# STM32WL3R register map
File version: 0.3
CPU: CM0+ r0p0, little endian, MPU, no FPU, 4 interrupt priority bits
Registers are 32-bit, read-write, reset 0x0 unless marked. A register's access mark holds for its fields unless they carry their own. Offsets are from the block's base; [hi:lo] are bit positions.

## DYNAMIC — DYNAMIC_REG_BLOCK address block description
Base 0x49000500
0x00 PCKTLEN_CONFIG reset 0x14
  [15:0] PCKTLEN — Length of packet in bytes for Normal mode with FIXED length mode
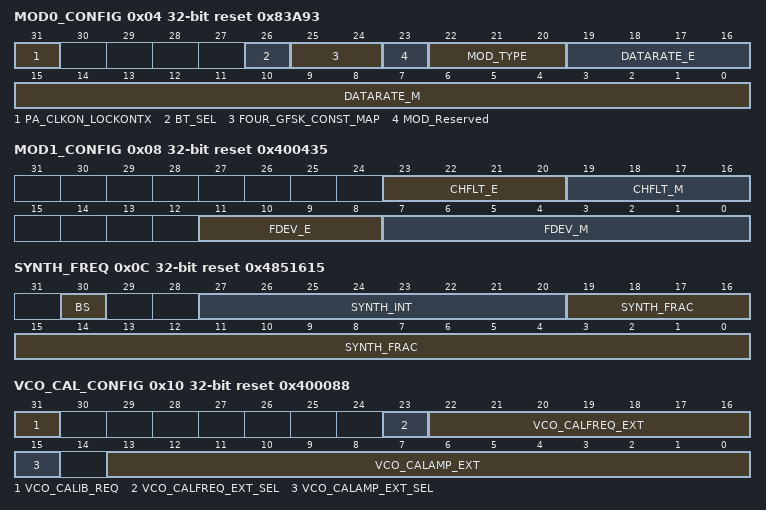
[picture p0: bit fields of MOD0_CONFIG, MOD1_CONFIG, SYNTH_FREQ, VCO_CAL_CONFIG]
0x04 MOD0_CONFIG reset 0x83A93
  [31] PA_CLKON_LOCKONTX — Enable the clock on analog PA in LOCKONTX state:
  [26] BT_SEL — Select BT value for GFSK (0.5 or 1)
  [25:24] FOUR_GFSK_CONST_MAP — 2- and 4-GFSK constellation mapping
  [23] MOD_Reserved — Free bit to expand MOD_TYPE in case more modulations to come in future evolutions
  [22:20] MOD_TYPE — Modulation type:
  [19:16] DATARATE_E — The exponent of the specified data rate (default: 38.4 ksps)
  [15:0] DATARATE_M — The Mantissa of the specified data rate (default: 38.4 ksps)
0x08 MOD1_CONFIG reset 0x400435
  [23:20] CHFLT_E — Exponent of the channel filter BW (default: 100 kHz)
  [19:16] CHFLT_M — Mantissa of the channel filter BW (default: 100 kHz)
  [11:8] FDEV_E — Exponent of the frequency deviation (default: 20 kHz)
  [7:0] FDEV_M — Mantissa of the frequency deviation (default: 20 kHz)
0x0C SYNTH_FREQ reset 0x4851615
  [30] BS — Synthesizer band selector, i.e. out-of-loop total divide factor, 4 or 8 (default: 826 MHz - 958 MHz band)
  [27:20] SYNTH_INT — PLL integer divide factor (default: 868 MHz, XTAL: 48 MHz)
  [19:0] SYNTH_FRAC — Fractional part of the PLL fractional divide factor
0x10 VCO_CAL_CONFIG reset 0x400088
  [31] VCO_CALIB_REQ — Define if the Radio FSM must launch a VCO calibration request after VCO start-up
  [23] VCO_CALFREQ_EXT_SEL — Bit to provide external VCO calfreq value through VCO_CALFREQ_EXT:
  [22:16] VCO_CALFREQ_EXT — VCO Cbank frequency calibration word.
  [15] VCO_CALAMP_EXT_SEL — Bit to provide external VCO calamp value through VCO_CALAMP_EXT:
  [13:0] VCO_CALAMP_EXT — VCO magnitude calibration word in thermometric code
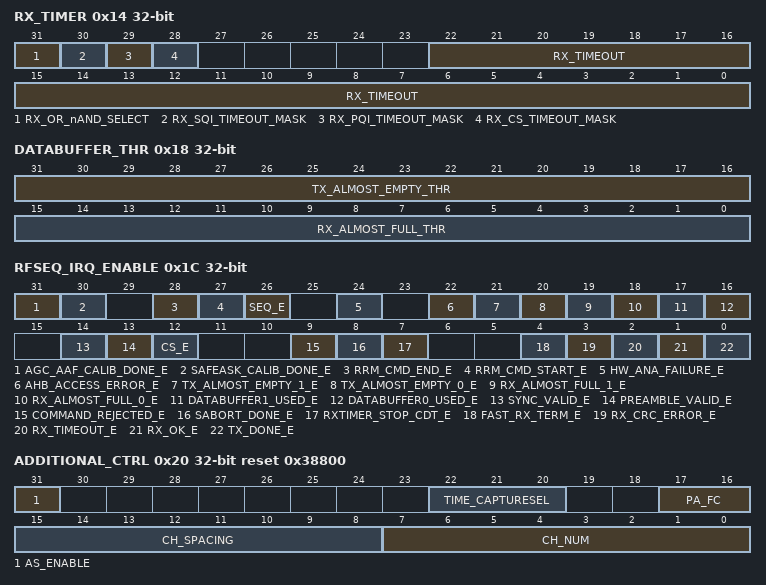
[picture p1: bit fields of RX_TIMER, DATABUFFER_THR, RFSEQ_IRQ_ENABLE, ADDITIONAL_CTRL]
0x14 RX_TIMER
  [31] RX_OR_nAND_SELECT — Select logical OR or logcial AND to apply on CS/PQI/SQI timeout mask:
  [30] RX_SQI_TIMEOUT_MASK — 1 => SQI value contributes to timeout disabling
  [29] RX_PQI_TIMEOUT_MASK — 1 => PQI value contributes to timeout disabling
  [28] RX_CS_TIMEOUT_MASK — 1 => CS value contributes to timeout disabling
  [22:0] RX_TIMEOUT — RX timer timeout (relative duration in interpolated time=machine time unit)
0x18 DATABUFFER_THR
  [31:16] TX_ALMOST_EMPTY_THR — Almost Empty threshold for TX DataBuffers.
  [15:0] RX_ALMOST_FULL_THR — Almost Full threshold for RX DataBuffers
0x1C RFSEQ_IRQ_ENABLE
  [31] AGC_AAF_CALIB_DONE_E — Enable interrupt on AGC_AAF_CALIB_DONE_F flag
  [30] SAFEASK_CALIB_DONE_E — Enable interrupt on SAFEASK_CALIB_DONE_F flag
  [28] RRM_CMD_END_E — Enable interrupt on RRM_CMD_END_F flag
  [27] RRM_CMD_START_E — Enable interrupt on RRM_CMD_START_F flag
  [26] SEQ_E — Enable interrupt on SEQ_F flag
  [24] HW_ANA_FAILURE_E — Enable interrupt on HW_ANA_FAILURE_F flag
  [22] AHB_ACCESS_ERROR_E — Enable interrupt on AHB_ACCESS_ERROR_F flag
  [21] TX_ALMOST_EMPTY_1_E — Enable interrupt on TX_ALMOST_EMPTY_1_F flag
  [20] TX_ALMOST_EMPTY_0_E — Enable interrupt on TX_ALMOST_EMPTY_0_F flag
  [19] RX_ALMOST_FULL_1_E — Enable interrupt on RX_ALMOST_FULL_1_F flag
  [18] RX_ALMOST_FULL_0_E — Enable interrupt on RX_ALMOST_FULL_0_F flag
  [17] DATABUFFER1_USED_E — Enable interrupt on DATABUFFER1_USED_F flag
  [16] DATABUFFER0_USED_E — Enable interrupt on DATABUFFER0_USED_F flag
  [14] SYNC_VALID_E — Enable interrupt on SYNC_VALIF_F flag
  [13] PREAMBLE_VALID_E — Enable interrupt on PREAMBLE_VALIF_F flag
  [12] CS_E — Enable interrupt on CS_F flag
  [9] COMMAND_REJECTED_E — Enable interrupt on COMMAND_REJECTED flag
  [8] SABORT_DONE_E — Enable interrupt on SABORT command treated and done flag
  [7] RXTIMER_STOP_CDT_E — Enable interrupt on RXTIMER_STOP_CDT_F flag
  [4] FAST_RX_TERM_E — Enable interrupt on FAST_RX_TERM_F flag
  [3] RX_CRC_ERROR_E — Enable interrupt on RX_CRC_ERROR_F flag
  [2] RX_TIMEOUT_E — Enable interrupt on RX_TIMEOUT_F flag
  [1] RX_OK_E — Enable interrupt on RX_OK_F flag
  [0] TX_DONE_E — Enable interrupt on TX_DONE_F flag
0x20 ADDITIONAL_CTRL reset 0x38800
  [31] AS_ENABLE — Enable antenna switching
  [22:20] TIME_CAPTURESEL — Select the trigger event that captures the absolute time in the TIME_CAPTURE[31:0] register
  [17:16] PA_FC — Power control bandwidth selection according datarate:
  [15:8] CH_SPACING — Channel spacing. From ~732 Hz to ~187 kHz in 732 Hz steps - default: 100 kHz.
  [7:0] CH_NUM — Channel number. This value is multiplied by the channel spacing and added to the synthesizer base frequency to generate the actual RF carrier frequency
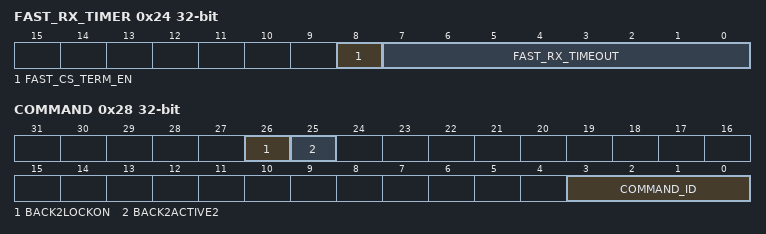
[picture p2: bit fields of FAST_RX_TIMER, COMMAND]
0x24 FAST_RX_TIMER
  [8] FAST_CS_TERM_EN — Fast RX Termination timer value.
  [7:0] FAST_RX_TIMEOUT — Timer unit is (2**CHFLT_E x 8) / sys_freq with sys_freq = 16 MHz
0x28 COMMAND
  [26] BACK2LOCKON — Target/return state for the Radio FSM when exiting a RX or a PA_DWN_ANA state is LOCKON.
  [25] BACK2ACTIVE2 — Default/return state for the Radio FSM is ACTIVE2
  [3:0] COMMAND_ID — Opcode coresponding to a command:

## Notices in the file
Copyright (c) 2025 STMicroelectronics.
SPDX-License-Identifier: Apache-2.0
Licensed under the Apache License, Version 2.0 (the "License");
you may not use this file except in compliance with the License.
You may obtain a copy of the License at
http://www.apache.org/licenses/LICENSE-2.0
Unless required by applicable law or agreed to in writing, software
distributed under the License is distributed on an "AS IS" BASIS,
WITHOUT WARRANTIES OR CONDITIONS OF ANY KIND, either express or implied.
See the License for the specific language governing permissions and
limitations under the License.
